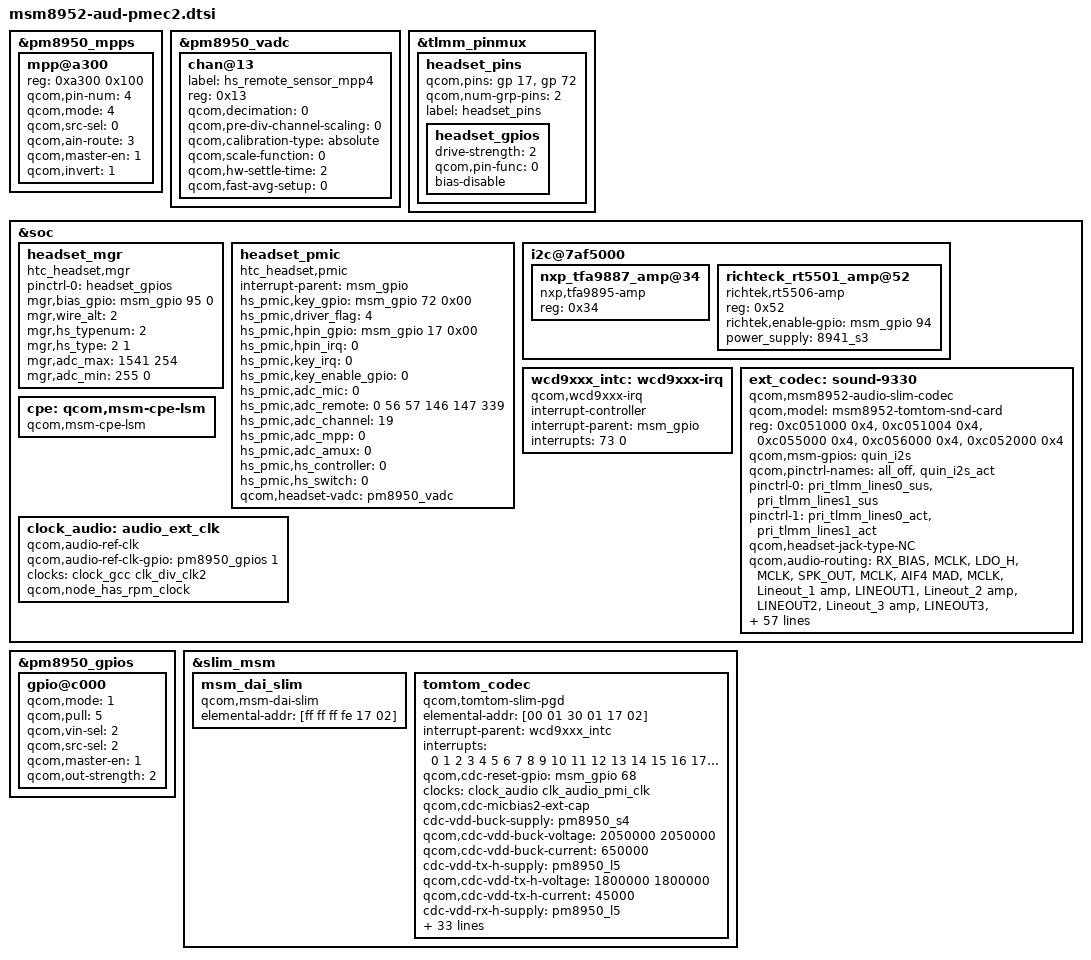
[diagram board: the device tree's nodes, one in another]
/* HIAE Audio Config */

// ================
//  HEADSET DRIVER
// ================

// msm-pm8950.dtsi has these settings, we replace this at here
&pm8950_mpps {
	mpp@a300 {
		reg = <0xa300 0x100>;
		qcom,pin-num = <4>;
		qcom,mode = <4>;	//QPNP_PIN_MODE_AIN
		qcom,src-sel = <0>;	//QPNP_PIN_SEL_FUNC_CONSTANT
		qcom,ain-route = <3>;	//QPNP_PIN_AIN_AMUX_CH
		qcom,master-en = <1>;	//ENABLE FEATURE
		qcom,invert = <1>;
		status = "ok";
	};
};

&pm8950_vadc {
	chan@13 {
		label = "hs_remote_sensor_mpp4";
		reg = <0x13>;
		qcom,decimation = <0>;			//512 sampling rate
		qcom,pre-div-channel-scaling = <0>;	//1:1 scaling
		qcom,calibration-type = "absolute";	//Use 625mV & 1.25V reference voltage
		qcom,scale-function = <0>;		//convert raw adc code to voltage
		qcom,hw-settle-time = <2>;		//200us
		qcom,fast-avg-setup = <0>;		//with only 1 average measurement
	};
};

&tlmm_pinmux {
	headset_pins {
		qcom,pins = <&gp 17>,<&gp 72>;
		qcom,num-grp-pins = <2>;
		label = "headset_pins";
		headset_gpios: headset_gpios {
			drive-strength = <2>;
			qcom,pin-func = <0>;
			bias-disable;	// NO PULL
		};
	};
};

&soc {
	headset_mgr {
		compatible   = "htc_headset,mgr";
		pinctrl-names = "headset_gpios";
		pinctrl-0 = <&headset_gpios>;
//		mgr,tx_gpio  = <&msm_gpio 0 0>;
//		mgr,rx_gpio  = <&msm_gpio 96 0>;
//		mgr,oe_gpio  = <&msm_gpio 0 0>;
		mgr,bias_gpio  = <&msm_gpio 95 0>;
		mgr,wire_alt = <2>;
		mgr,hs_typenum	 = <2>;
		mgr,hs_type	 = <2 1>;
		mgr,adc_max	 = <1541 254>;
		mgr,adc_min	 = <255 0>;
	};

	headset_pmic {
		compatible = "htc_headset,pmic";
		interrupt-parent = <&msm_gpio>;
		hs_pmic,key_gpio	= <&msm_gpio 72 0x00>;
		hs_pmic,driver_flag	= <4>;
		hs_pmic,hpin_gpio	= <&msm_gpio 17 0x00>;
		hs_pmic,hpin_irq	= <0>;
		hs_pmic,key_irq 	= <0>;
		hs_pmic,key_enable_gpio = <0>;
		hs_pmic,adc_mic 	= <0>;
		hs_pmic,adc_remote	= <0 56 57 146 147 339>;
		hs_pmic,adc_channel	= <19>; //MPP4
		hs_pmic,adc_mpp 	= <0>;
		hs_pmic,adc_amux	= <0>;
		hs_pmic,hs_controller	= <0>;
		hs_pmic,hs_switch	= <0>;
		qcom,headset-vadc	= <&pm8950_vadc>;
	};

//	headset_onewire {
//		compatible = "htc_headset,1wire";
//		hs_1wire,tx_level_shift_en = <&msm_gpio 0 0x00>;
//		hs_1wire,one_wire_remote = <0x7E 0x7F 0x7D 0x7F 0x7B 0x7F>;
//		hs_1wire,onewire_tty_dev = "ttyHSL1";
//	};
};


// ================
//  AUDIO and CODE
// ================


//&int_codec {
//	status = "disabled";
//};
//&pm8950_cajon_dig {
//	status = "disabled";
//};
//&pm8950_cajon_analog {
//	status = "disabled";
//};

&pm8950_gpios {
// gpio@c000: WCD9330 MCLK
	gpio@c000 {
		status = "ok";
		qcom,mode = <1>;
		qcom,pull = <5>;
		qcom,vin-sel = <2>;
		qcom,src-sel = <2>;
		qcom,master-en = <1>;
		qcom,out-strength = <2>;
	};
};

// eldo2
//&pmi8950_gpios {
//	gpio@c000 {
//		status = "ok";
//		qcom,mode = <1>;
//		qcom,pull = <5>;
//		qcom,vin-sel = <2>;
//		qcom,src-sel = <2>;
//		qcom,master-en = <1>;
//		qcom,out-strength = <2>;
//	};
//}
//&soc {
//	eldo2_8952: eldo2 {
//		compatible = "regulator-fixed";
//		regulator-name = "eldo2_8952";
//		startup-delay-us = <0>;
//		enable-active-high;
//		gpio = <&pm8950_gpios 7 0>;
//	};
//};

&soc {
	i2c@7af5000 {
		nxp_tfa9887_amp@34 {
			compatible = "nxp,tfa9895-amp";
			reg = <0x34>;
		};
		richteck_rt5501_amp@52 {
			compatible = "richtek,rt5506-amp";
			reg = <0x52>;
			richtek,enable-gpio = <&msm_gpio 94 0x00>;
			power_supply = "8941_s3";
		};
	};

	wcd9xxx_intc: wcd9xxx-irq {
		compatible = "qcom,wcd9xxx-irq";
		interrupt-controller;
		#interrupt-cells = <1>;
		interrupt-parent = <&msm_gpio>;
		interrupts = <73 0>;
		interrupt-names = "cdc-int";
	};

	ext_codec: sound-9330 {
		compatible = "qcom,msm8952-audio-slim-codec";
		qcom,model = "msm8952-tomtom-snd-card";

		reg = <0xc051000 0x4>,
		    <0xc051004 0x4>,
		    <0xc055000 0x4>,
		    <0xc056000 0x4>,
		    <0xc052000 0x4>;
		reg-names = "csr_gp_io_mux_mic_ctl",
			"csr_gp_io_mux_spkr_ctl",
			"csr_gp_io_lpaif_pri_pcm_pri_mode_muxsel",
			"csr_gp_io_lpaif_sec_pcm_sec_mode_muxsel",
			"csr_gp_io_mux_quin_ctl";
		qcom,msm-gpios =
			"quin_i2s";
		qcom,pinctrl-names =
			"all_off",
			"quin_i2s_act";
		pinctrl-names =
			"all_off",
			"quin_i2s_act";
		pinctrl-0 = <&pri_tlmm_lines0_sus &pri_tlmm_lines1_sus>;
		pinctrl-1 = <&pri_tlmm_lines0_act &pri_tlmm_lines1_act>;

		qcom,headset-jack-type-NC;
		qcom,audio-routing =
			"RX_BIAS", "MCLK",
			"LDO_H", "MCLK",
			"SPK_OUT", "MCLK",
			"AIF4 MAD", "MCLK",

			"Lineout_1 amp", "LINEOUT1",
			"Lineout_2 amp", "LINEOUT2",
			"Lineout_3 amp", "LINEOUT3",
			"Lineout_4 amp", "LINEOUT4",

			"AMIC1", "MIC BIAS1 External",
			"MIC BIAS1 External", "Handset Mic",
			"AMIC2", "MIC BIAS2 External",
			"MIC BIAS2 External", "Headset Mic",
			"AMIC3", "MIC BIAS3 External",
			"MIC BIAS3 External", "ANCRight Headset Mic",
			"MIC BIAS4 External", "Digital Mic6",
			"MIC BIAS1 Internal1", "MICBIAS_REGULATOR",
			"MIC BIAS1 Internal2", "MICBIAS_REGULATOR",
			"MIC BIAS1 External", "MICBIAS_REGULATOR",
			"MIC BIAS2 Internal1", "MICBIAS_REGULATOR",
			"MIC BIAS2 Internal2", "MICBIAS_REGULATOR",
			"MIC BIAS2 Internal3", "MICBIAS_REGULATOR",
			"MIC BIAS2 External", "MICBIAS_REGULATOR",
			"MIC BIAS3 Internal1", "MICBIAS_REGULATOR",
			"MIC BIAS3 Internal2", "MICBIAS_REGULATOR",
			"MIC BIAS3 External", "MICBIAS_REGULATOR",
			"MIC BIAS4 External", "MICBIAS_REGULATOR"; //end
/*
			"AMIC4", "MIC BIAS2 External",
			"MIC BIAS2 External", "ANCLeft Headset Mic",
			"AMIC5", "MIC BIAS3 External",
			"MIC BIAS3 External", "Handset Mic",
			"AMIC6", "MIC BIAS4 External",
			"MIC BIAS4 External", "Handset Mic",
			"DMIC1", "MIC BIAS1 External",
			"MIC BIAS1 External", "Digital Mic1",
			"DMIC2", "MIC BIAS1 External",
			"MIC BIAS1 External", "Digital Mic2",
			"DMIC3", "MIC BIAS3 External",
			"MIC BIAS3 External", "Digital Mic3",
			"DMIC4", "MIC BIAS3 External",
			"MIC BIAS3 External", "Digital Mic4",
			"DMIC5", "MIC BIAS4 External",
			"MIC BIAS4 External", "Digital Mic5",
			"DMIC6", "MIC BIAS4 External",
			"MIC BIAS4 External", "Digital Mic6";
*/

		asoc-platform = <&pcm0>, <&pcm1>, <&pcm2>, <&voip>, <&voice>,
				<&loopback>, <&compress>, <&hostless>,
				<&afe>, <&lsm>, <&routing>, <&lpa>, <&cpe>;
		asoc-platform-names = "msm-pcm-dsp.0", "msm-pcm-dsp.1", "msm-pcm-dsp.2",
				"msm-voip-dsp", "msm-pcm-voice", "msm-pcm-loopback",
				"msm-compress-dsp", "msm-pcm-hostless", "msm-pcm-afe",
				"msm-lsm-client", "msm-pcm-routing", "msm-pcm-lpa",
				"msm-cpe-lsm";
		asoc-cpu = <&dai_hdmi>, <&dai_mi2s0>, <&dai_mi2s1>,
				<&dai_mi2s2>, <&dai_mi2s3>, <&dai_mi2s5>, <&sb_0_rx>, <&sb_0_tx>,
				<&sb_1_rx>, <&sb_1_tx>, <&sb_3_rx>, <&sb_3_tx>,
				<&sb_4_rx>, <&sb_4_tx>, <&sb_5_tx>, <&bt_sco_rx>,
				<&bt_sco_tx>, <&int_fm_rx>, <&int_fm_tx>, <&afe_pcm_rx>,
				<&afe_pcm_tx>, <&afe_proxy_rx>, <&afe_proxy_tx>,
				<&incall_record_rx>, <&incall_record_tx>, <&incall_music_rx>,
				<&incall_music_2_rx>;
		asoc-cpu-names = "msm-dai-q6-hdmi.8", "msm-dai-q6-mi2s.0",
				"msm-dai-q6-mi2s.1", "msm-dai-q6-mi2s.2",
				"msm-dai-q6-mi2s.3",
				"msm-dai-q6-mi2s.5", "msm-dai-q6-dev.16384",
				"msm-dai-q6-dev.16385", "msm-dai-q6-dev.16386",
				"msm-dai-q6-dev.16387", "msm-dai-q6-dev.16390",
				"msm-dai-q6-dev.16391", "msm-dai-q6-dev.16392",
				"msm-dai-q6-dev.16393", "msm-dai-q6-dev.16395",
				"msm-dai-q6-dev.12288", "msm-dai-q6-dev.12289",
				"msm-dai-q6-dev.12292", "msm-dai-q6-dev.12293",
				"msm-dai-q6-dev.224", "msm-dai-q6-dev.225",
				"msm-dai-q6-dev.241", "msm-dai-q6-dev.240",
				"msm-dai-q6-dev.32771", "msm-dai-q6-dev.32772",
				"msm-dai-q6-dev.32773", "msm-dai-q6-dev.32770";
		asoc-codec = <&stub_codec>;
		asoc-codec-names = "msm-stub-codec.1";
		qcom,msm-ext-pa = "quinary";

		hset-amp-gpio-en = <&msm_gpio 94 0>;
		rcv-ldo-gpio-en	= <&msm_gpio 22 0>;
		rcv-amp-gpio-en	= <&msm_gpio 23 0>;

		htc,aud-component-list =
			"RT5507",
			"TPA6185",
			"TFA9895";
	};

	cpe: qcom,msm-cpe-lsm {
		compatible = "qcom,msm-cpe-lsm";
	};

	clock_audio: audio_ext_clk {
		compatible = "qcom,audio-ref-clk";
		qcom,audio-ref-clk-gpio = <&pm8950_gpios 1 0>;
		clock-names = "osr_clk";
		clocks = <&clock_gcc clk_div_clk2>;
		qcom,node_has_rpm_clock;
		#clock-cells = <1>;
	};
};

&slim_msm {
	status = "ok";
	msm_dai_slim {
		compatible = "qcom,msm-dai-slim";
		elemental-addr = [ff ff ff fe 17 02];
	};

	tomtom_codec {
		compatible = "qcom,tomtom-slim-pgd";
		elemental-addr = [00 01 30 01 17 02];

		interrupt-parent = <&wcd9xxx_intc>;
		interrupts = <0 1 2 3 4 5 6 7 8 9 10 11 12 13 14 15 16
			17 18 19 20 21 22 23 24 25 26 27 28 29
			30 31>;

		qcom,cdc-reset-gpio = <&msm_gpio 68 0>;

		clock-names = "wcd_clk";
		clocks = <&clock_audio clk_audio_pmi_clk>;

		qcom,cdc-micbias2-ext-cap;

//		cdc-vdd-buck-supply = <&eldo2_8952>;
//		qcom,cdc-vdd-buck-voltage = <1800000 2150000>;

		cdc-vdd-buck-supply = <&pm8950_s4>;
		qcom,cdc-vdd-buck-voltage = <2050000 2050000>;
		qcom,cdc-vdd-buck-current = <650000>;

		cdc-vdd-tx-h-supply = <&pm8950_l5>;
		qcom,cdc-vdd-tx-h-voltage = <1800000 1800000>;
		qcom,cdc-vdd-tx-h-current = <45000>;

		cdc-vdd-rx-h-supply = <&pm8950_l5>;
		qcom,cdc-vdd-rx-h-voltage = <1800000 1800000>;
		qcom,cdc-vdd-rx-h-current = <45000>;

		cdc-vdd-px-supply = <&pm8950_l5>;
		qcom,cdc-vdd-px-voltage = <1800000 1800000>;
		qcom,cdc-vdd-px-current = <45000>;

		cdc-vddcx-1-supply = <&pm8950_l2>;
		qcom,cdc-vddcx-1-voltage = <1200000 1200000>;
		qcom,cdc-vddcx-1-current = <35000>;

//		cdc-vddcx-2-supply = <&pm8950_s3>;
//		qcom,cdc-vddcx-2-voltage = <1300000 1300000>;
//		qcom,cdc-vddcx-2-current = <20000>;

		cdc-vddcx-2-supply = <&pm8950_l2>;
		qcom,cdc-vddcx-2-voltage = <1200000 1200000>;
		qcom,cdc-vddcx-2-current = <35000>;

		cdc-vdd-mic-bias-supply = <&pm8950_l13>;
		qcom,cdc-vdd-mic-bias-voltage = <3075000 3075000>;
		qcom,cdc-vdd-mic-bias-current = <15000>;

		qcom,cdc-static-supplies = "cdc-vdd-buck",
			"cdc-vdd-tx-h",
			"cdc-vdd-rx-h",
			"cdc-vdd-px",
			"cdc-vddcx-1",
			"cdc-vddcx-2";

		qcom,cdc-on-demand-supplies = "cdc-vdd-mic-bias";

		qcom,cdc-cp-supplies = "cdc-vdd-buck";
		qcom,cdc-micbias-ldoh-v = <0x3>;
		qcom,cdc-micbias-cfilt1-mv = <1800>;
		qcom,cdc-micbias-cfilt2-mv = <2700>;
		qcom,cdc-micbias-cfilt3-mv = <1800>;
		qcom,cdc-micbias1-cfilt-sel = <0x0>;
		qcom,cdc-micbias2-cfilt-sel = <0x1>;
		qcom,cdc-micbias3-cfilt-sel = <0x2>;
		qcom,cdc-micbias4-cfilt-sel = <0x2>;
		qcom,cdc-mclk-clk-rate = <9600000>;
		qcom,cdc-slim-ifd = "tomtom-slim-ifd";
		qcom,cdc-slim-ifd-elemental-addr = [00 00 30 01 17 02];
		qcom,cdc-dmic-sample-rate = <2400000>;
		qcom,cdc-variant = "WCD9330";
	};
};
